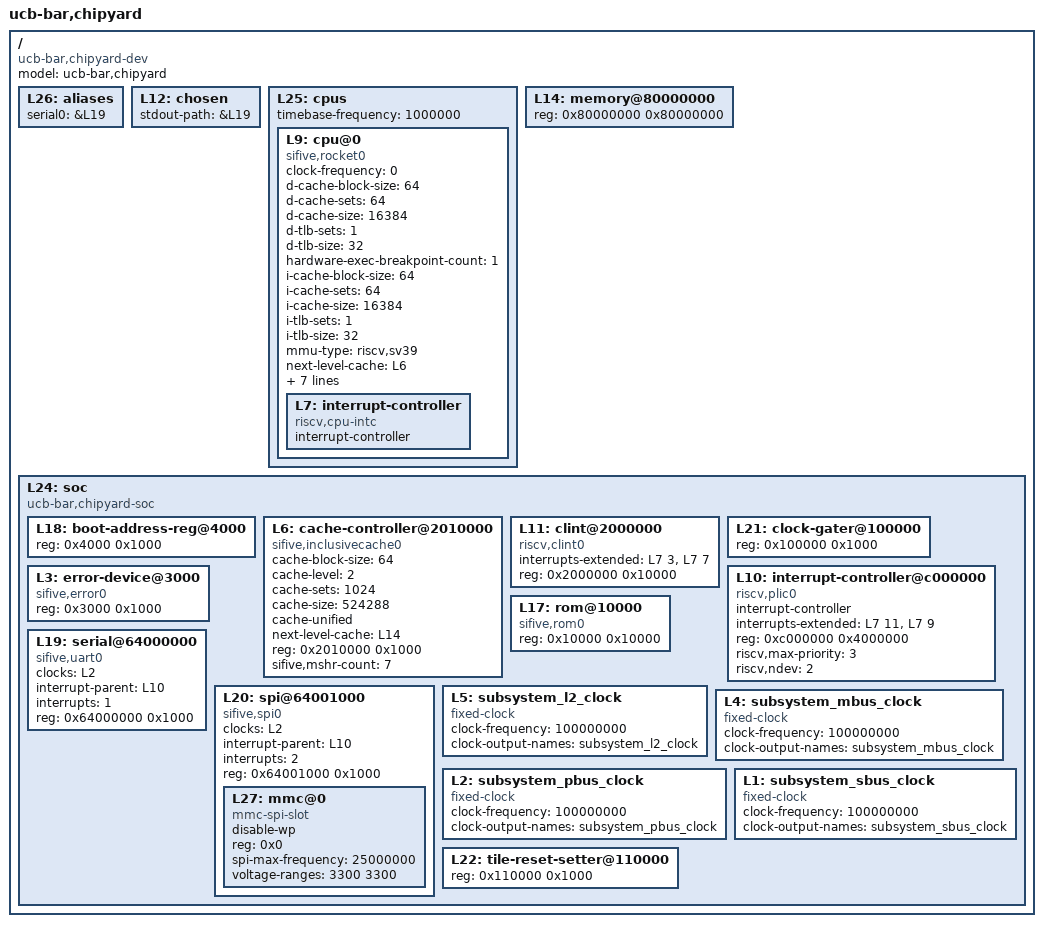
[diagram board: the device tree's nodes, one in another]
/dts-v1/;

/ {
	#address-cells = <1>;
	#size-cells = <1>;
	compatible = "ucb-bar,chipyard-dev";
	model = "ucb-bar,chipyard";
	L26: aliases {
		serial0 = &L19;
	};
	L12: chosen {
		stdout-path = &L19;
	};
	L25: cpus {
		#address-cells = <1>;
		#size-cells = <0>;
		timebase-frequency = <1000000>;
		L9: cpu@0 {
			clock-frequency = <0>;
			compatible = "sifive,rocket0", "riscv";
			d-cache-block-size = <64>;
			d-cache-sets = <64>;
			d-cache-size = <16384>;
			d-tlb-sets = <1>;
			d-tlb-size = <32>;
			device_type = "cpu";
			hardware-exec-breakpoint-count = <1>;
			i-cache-block-size = <64>;
			i-cache-sets = <64>;
			i-cache-size = <16384>;
			i-tlb-sets = <1>;
			i-tlb-size = <32>;
			mmu-type = "riscv,sv39";
			next-level-cache = <&L6>;
			reg = <0x0>;
			riscv,isa = "rv64imafdcvzicsr_zifencei_zihpm_xrocket";
			riscv,pmpgranularity = <4>;
			riscv,pmpregions = <16>;
			status = "okay";
			timebase-frequency = <1000000>;
			tlb-split;
			L7: interrupt-controller {
				#interrupt-cells = <1>;
				compatible = "riscv,cpu-intc";
				interrupt-controller;
			};
		};
	};
	L14: memory@80000000 {
		device_type = "memory";
		reg = <0x80000000 0x80000000>;
	};
	L24: soc {
		#address-cells = <1>;
		#size-cells = <1>;
		compatible = "ucb-bar,chipyard-soc", "simple-bus";
		ranges;
		L18: boot-address-reg@4000 {
			reg = <0x4000 0x1000>;
			reg-names = "control";
		};
		L6: cache-controller@2010000 {
			cache-block-size = <64>;
			cache-level = <2>;
			cache-sets = <1024>;
			cache-size = <524288>;
			cache-unified;
			compatible = "sifive,inclusivecache0", "cache";
			next-level-cache = <&L14>;
			reg = <0x2010000 0x1000>;
			reg-names = "control";
			sifive,mshr-count = <7>;
		};
		L11: clint@2000000 {
			compatible = "riscv,clint0";
			interrupts-extended = <&L7 3 &L7 7>;
			reg = <0x2000000 0x10000>;
			reg-names = "control";
		};
		L21: clock-gater@100000 {
			reg = <0x100000 0x1000>;
			reg-names = "control";
		};
		L3: error-device@3000 {
			compatible = "sifive,error0";
			reg = <0x3000 0x1000>;
		};
		L10: interrupt-controller@c000000 {
			#interrupt-cells = <1>;
			compatible = "riscv,plic0";
			interrupt-controller;
			interrupts-extended = <&L7 11 &L7 9>;
			reg = <0xc000000 0x4000000>;
			reg-names = "control";
			riscv,max-priority = <3>;
			riscv,ndev = <2>;
		};
		L17: rom@10000 {
			compatible = "sifive,rom0";
			reg = <0x10000 0x10000>;
			reg-names = "mem";
		};
		L19: serial@64000000 {
			clocks = <&L2>;
			compatible = "sifive,uart0";
			interrupt-parent = <&L10>;
			interrupts = <1>;
			reg = <0x64000000 0x1000>;
			reg-names = "control";
		};
		L20: spi@64001000 {
			#address-cells = <1>;
			#size-cells = <0>;
			clocks = <&L2>;
			compatible = "sifive,spi0";
			interrupt-parent = <&L10>;
			interrupts = <2>;
			reg = <0x64001000 0x1000>;
			reg-names = "control";
			L27: mmc@0 {
				compatible = "mmc-spi-slot";
				disable-wp;
				reg = <0x0>;
				spi-max-frequency = <25000000>;
				voltage-ranges = <3300 3300>;
			};
		};
		L5: subsystem_l2_clock {
			#clock-cells = <0>;
			clock-frequency = <100000000>;
			clock-output-names = "subsystem_l2_clock";
			compatible = "fixed-clock";
		};
		L4: subsystem_mbus_clock {
			#clock-cells = <0>;
			clock-frequency = <100000000>;
			clock-output-names = "subsystem_mbus_clock";
			compatible = "fixed-clock";
		};
		L2: subsystem_pbus_clock {
			#clock-cells = <0>;
			clock-frequency = <100000000>;
			clock-output-names = "subsystem_pbus_clock";
			compatible = "fixed-clock";
		};
		L1: subsystem_sbus_clock {
			#clock-cells = <0>;
			clock-frequency = <100000000>;
			clock-output-names = "subsystem_sbus_clock";
			compatible = "fixed-clock";
		};
		L22: tile-reset-setter@110000 {
			reg = <0x110000 0x1000>;
			reg-names = "control";
		};
	};
};
